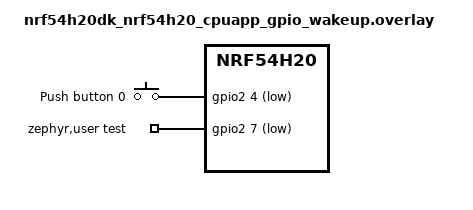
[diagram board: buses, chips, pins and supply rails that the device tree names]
/ {
	aliases {
		/delete-property/ sw1;
	};

	/*
	 * Redefine sw0/button0 to use RXD0 - P2.04
	 * Thus, when sending character from host, there will be gpio interrupt,
	 * the same as originally triggered by sw0 button.
	 */
	buttons {
		compatible = "gpio-keys";

		button0: button_0 {
			gpios = <&gpio2 4 (GPIO_PULL_UP | GPIO_ACTIVE_LOW)>;
			label = "Push button 0";
			zephyr,code = <INPUT_KEY_0>;
		};
	};

	zephyr,user {
		test-gpios = <&gpio2 7 GPIO_ACTIVE_LOW>;
	};
};

/delete-node/ &button1;

&gpiote130 {
	status = "okay";
	owned-channels = <0>;
};

&gpio2 {
	status = "okay";
};
